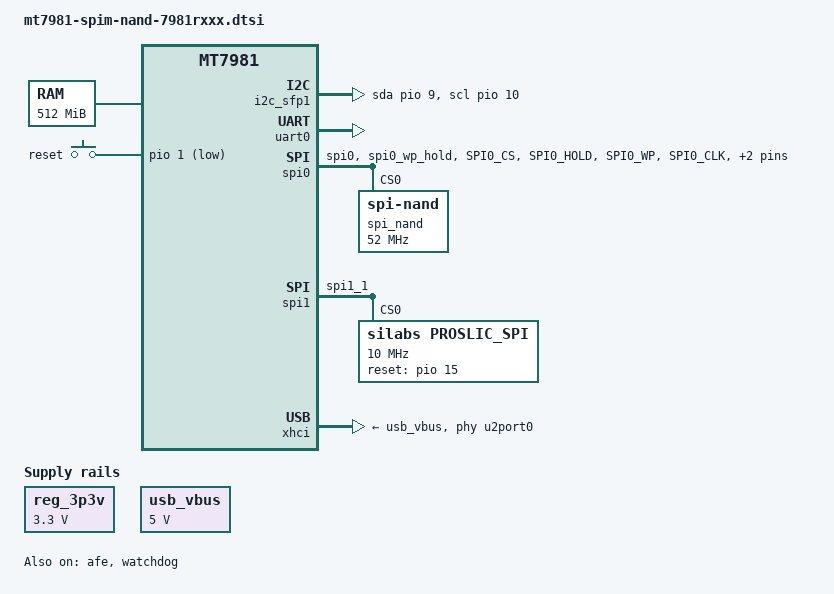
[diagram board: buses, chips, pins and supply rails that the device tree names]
// SPDX-License-Identifier: (GPL-2.0-or-later OR MIT)
/*
 * Copyright Zhaolaibin's SX-7981R128 Update By nanchuci
 */

/dts-v1/;
#include <dt-bindings/gpio/gpio.h>
#include <dt-bindings/input/input.h>

#include "mt7981.dtsi"

/ {
	aliases {
		led-boot = &POWER;
		led-failsafe = &POWER;
		led-running = &POWER;
		led-upgrade = &POWER;
	};

	chosen {
		bootargs = "console=ttyS0,115200n1 loglevel=8  \
				earlycon=uart8250,mmio32,0x11002000";
	};

	memory {
		// ddr4: 512MB
		reg = <0 0x40000000 0 0x20000000>;
	};

	gpio-keys {
		compatible = "gpio-keys";

		reset-button {
			label = "reset";
			linux,code = <KEY_RESTART>;
			gpios = <&pio 1 GPIO_ACTIVE_LOW>;
		};
	};

	i2c_sfp1: i2c-gpio-0 {
		compatible = "i2c-gpio";
		sda-gpios = <&pio 9 (GPIO_ACTIVE_HIGH | GPIO_OPEN_DRAIN)>;
		scl-gpios = <&pio 10 (GPIO_ACTIVE_HIGH | GPIO_OPEN_DRAIN)>;
		i2c-gpio,delay-us = <2>;
		#address-cells = <1>;
		#size-cells = <0>;
	};

	reg_3p3v: regulator-3p3v {
		compatible = "regulator-fixed";
		regulator-name = "fixed-3.3V";
		regulator-min-microvolt = <3300000>;
		regulator-max-microvolt = <3300000>;
		regulator-boot-on;
		regulator-always-on;
	};

	usb_vbus: regulator-usb-vbus {
		compatible = "regulator-fixed";
		regulator-name = "usb_vbus";
		regulator-min-microvolt = <5000000>;
		regulator-max-microvolt = <5000000>;
		enable-active-high;
		regulator-boot-on;
	};

	nmbm_spim_nand {
		compatible = "generic,nmbm";

		#address-cells = <1>;
		#size-cells = <1>;

		lower-mtd-device = <&spi_nand>;
		forced-create;

		partitions {
			compatible = "fixed-partitions";
			#address-cells = <1>;
			#size-cells = <1>;

			partition@0 {
				label = "BL2";
				reg = <0x00000 0x0100000>;
				#read-only;
			};

			partition@100000 {
				label = "u-boot-env";
				reg = <0x0100000 0x0080000>;
			};

			factory: partition@180000 {
				label = "Factory";
				reg = <0x180000 0x0200000>;
			};

			partition@380000 {
				label = "FIP";
				reg = <0x380000 0x0200000>;
			};

			partition@580000 {
				label = "ubi";
				// reg = <0x580000 0x4000000>;
				reg = <0x580000 0x7280000>;
			};
		};
	};
};

&afe {
	pinctrl-names = "default";
	pinctrl-0 = <&pcm_pins>;
	status = "okay";
};

&i2c0 {
	pinctrl-names = "default";
	pinctrl-0 = <&i2c_pins>;
	status = "disabled";
};

&uart0 {
	status = "okay";
};

&watchdog {
	status = "okay";
};

&spi0 {
	pinctrl-names = "default";
	pinctrl-0 = <&spi0_flash_pins>;
	status = "okay";

	spi_nand: spi_nand@0 {
		#address-cells = <1>;
		#size-cells = <1>;
		compatible = "spi-nand";
		reg = <0>;
		spi-max-frequency = <52000000>;
		spi-tx-bus-width = <4>;
		spi-rx-bus-width = <4>;
		spi-cal-enable;
		spi-cal-mode = "read-data";
		spi-cal-datalen = <7>;
		spi-cal-data = /bits/ 8 <0x53 0x50 0x49 0x4E 0x41 0x4E 0x44>; /* 'SPINAND' */
		spi-cal-addrlen = <5>;
		spi-cal-addr = /bits/ 32 <0x0 0x0 0x0 0x0 0x0>;
	};
};

&spi1 {
	pinctrl-names = "default";
	pinctrl-0 = <&spic_pins>;
	status = "okay";

	proslic_spi: proslic_spi@0 {
		compatible = "silabs,proslic_spi";
		reg = <0>;
		spi-max-frequency = <10000000>;
		spi-cpha = <1>;
		spi-cpol = <1>;
		channel_count = <1>;
		debug_level = <4>;       /* 1 = TRC, 2 = DBG, 4 = ERR */
		reset_gpio = <&pio 15 0>;
		ig,enable-spi = <1>;     /* 1: Enable, 0: Disable */
	};
};

&pio {
	i2c_pins: i2c-pins-g0 {
		mux {
			function = "i2c";
			groups = "i2c0_0";
		};
	};

	pcm_pins: pcm-pins-g0 {
		mux {
			function = "pcm";
			groups = "pcm";
		};
	};

	pwm0_pin: pwm0-pin-g0 {
		mux {
			function = "pwm";
			groups = "pwm0_0";
		};
	};

	pwm1_pin: pwm1-pin-g0 {
		mux {
			function = "pwm";
			groups = "pwm1_0";
		};
	};

	pwm2_pin: pwm2-pin {
		mux {
			function = "pwm";
			groups = "pwm2";
		};
	};

	spi0_flash_pins: spi0-pins {
		mux {
			function = "spi";
			groups = "spi0", "spi0_wp_hold";
		};

		conf-pu {
			pins = "SPI0_CS", "SPI0_HOLD", "SPI0_WP";
			drive-strength = <MTK_DRIVE_8mA>;
			bias-pull-up = <MTK_PUPD_SET_R1R0_11>;
		};

		conf-pd {
			pins = "SPI0_CLK", "SPI0_MOSI", "SPI0_MISO";
			drive-strength = <MTK_DRIVE_8mA>;
			bias-pull-down = <MTK_PUPD_SET_R1R0_11>;
		};
	};

	spic_pins: spi1-pins {
		mux {
			function = "spi";
			groups = "spi1_1";
		};
	};

	uart1_pins: uart1-pins-g1 {
		mux {
			function = "uart";
			groups = "uart1_1";
		};
	};

	uart2_pins: uart2-pins-g1 {
		mux {
			function = "uart";
			groups = "uart2_1";
		};
	};
};

&xhci {
	mediatek,u3p-dis-msk = <0x0>;
	phys = <&u2port0 PHY_TYPE_USB2>,
	       <&u3port0 PHY_TYPE_USB3>;
	vusb33-supply = <&reg_3p3v>;
	vbus-supply = <&usb_vbus>;
	status = "okay";
};
